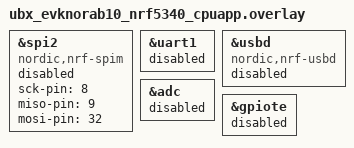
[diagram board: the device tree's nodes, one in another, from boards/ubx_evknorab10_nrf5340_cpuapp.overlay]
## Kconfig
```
#
# Copyright (c) 2018 Nordic Semiconductor
#
# SPDX-License-Identifier: LicenseRef-Nordic-5-Clause
#

source "Kconfig.zephyr"

menu "Nordic UART BLE GATT service sample"



endmenu
```

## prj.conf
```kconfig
#
# Copyright (c) 2018 Nordic Semiconductor
#
# SPDX-License-Identifier: LicenseRef-Nordic-5-Clause
#
CONFIG_PM=y
#CONFIG_PM_DEEP_SLEEP_STATES=y  #WRC what is change since V1.5.1

# Required to disable default behavior of deep sleep on timeout
CONFIG_PM_DEVICE=y
CONFIG_GPIO=n 
CONFIG_SPI=n
CONFIG_I2C=n

CONFIG_HEAP_MEM_POOL_SIZE=100000

CONFIG_CONSOLE=n
CONFIG_UART_CONSOLE=n
CONFIG_LOG=n
CONFIG_SERIAL=n
CONFIG_USE_SEGGER_RTT=n
CONFIG_LOG_BACKEND_RTT=n
CONFIG_LOG_BACKEND_UART=n
# Some command handlers require a large stack.
CONFIG_SYSTEM_WORKQUEUE_STACK_SIZE=4096
```

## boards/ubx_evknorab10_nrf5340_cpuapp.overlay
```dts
&spi2 {
	compatible = "nordic,nrf-spim";
	status = "disabled";
	sck-pin = <8>;  // original 8
	miso-pin = <9>;  // original 9
	mosi-pin = <32>;  // original 10
};

// /{
// 	leds {
// 		compatible = "gpio-leds";
// 		led0: led_0 {
// 			gpios = <&gpio0 30 GPIO_ACTIVE_HIGH>;
// 			label = "BLE LED";
// 		};

// 		led1: led_1 {
// 			gpios = <&gpio0 31 GPIO_ACTIVE_HIGH>;
// 			label = "DEBUG LED";
// 		};
// 	};
// };

// &uart0{
// 	status = "okay";
// 	current-speed = <115200>;
// 	// tx-pin = <45>;
// 	// rx-pin = <44>;
// };

&uart1{

    status="disabled";
};

&usbd {
	compatible = "nordic,nrf-usbd";
	status = "disabled";
};

&adc {
	status = "disabled";
};

&gpiote {
	status = "disabled";
};

// &pwm0 {
// 	status = "disabled"
// }

// &timer1 {
// 	status = "disabled"
// }

// &timer2 {
// 	status = "disabled"
// }

// &qspi {
// 	status = "disabled"
// }
```

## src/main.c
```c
#include <stdio.h>
#include <zephyr.h>
#include <pm/pm.h>

void main(void)
{
	int i = 3;
	pm_constraint_set(PM_STATE_SOFT_OFF);
	// for (;;) {

	// }
}
```
